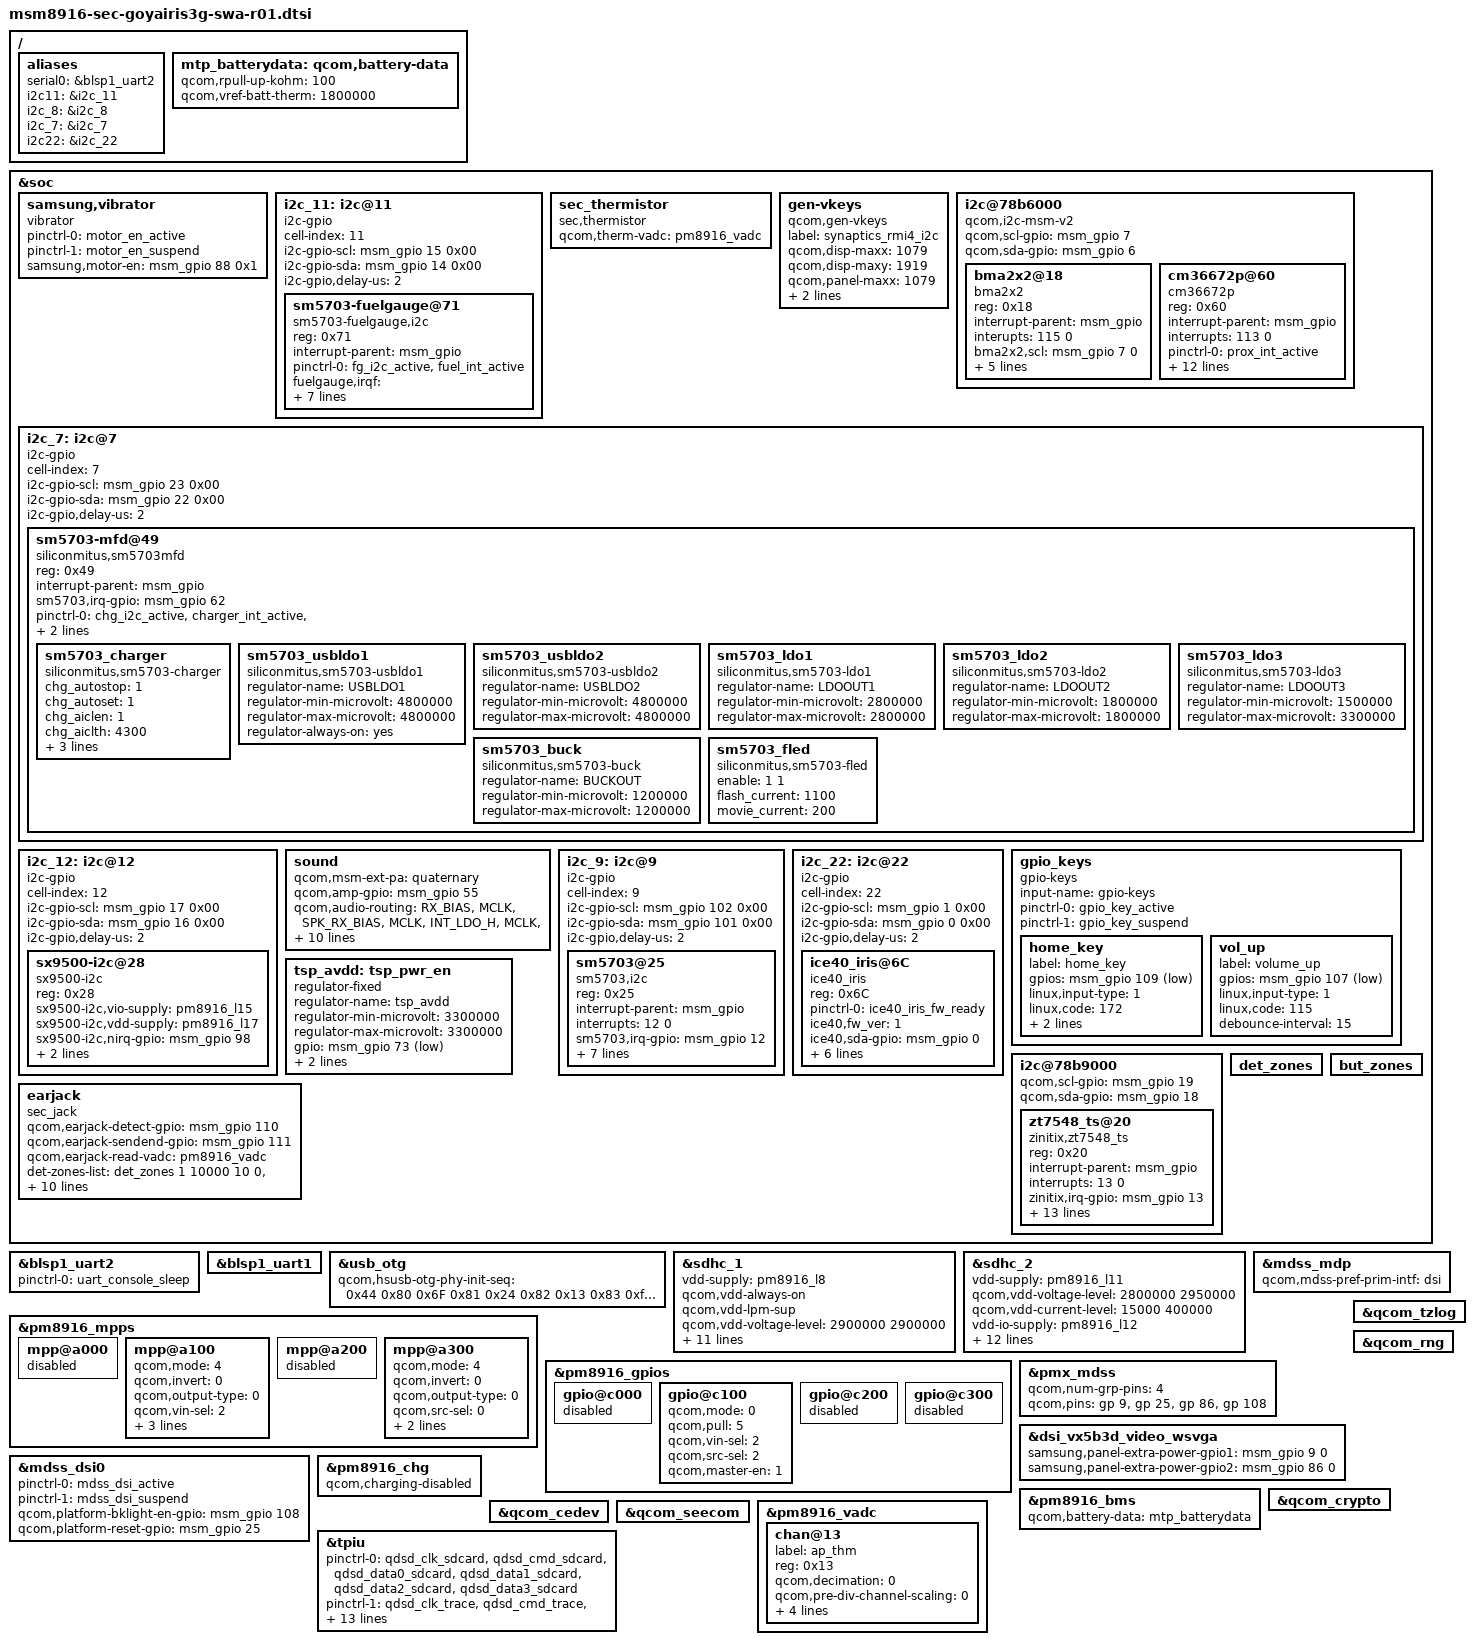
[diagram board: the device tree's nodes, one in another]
/* Copyright (c) 2014, The Linux Foundation. All rights reserved.
 *
 * This program is free software; you can redistribute it and/or modify
 * it under the terms of the GNU General Public License version 2 and
 * only version 2 as published by the Free Software Foundation.
 *
 * This program is distributed in the hope that it will be useful,
 * but WITHOUT ANY WARRANTY; without even the implied warranty of
 * MERCHANTABILITY or FITNESS FOR A PARTICULAR PURPOSE.  See the
 * GNU General Public License for more details.
 */

#include "msm8916.dtsi"
#include "msm8916-pinctrl-sec-goyairis3g-swa-r01.dtsi"
#include "msm8916-camera-sensor-goyairis3g-swa-r01.dtsi"
#include "msm8916-sec-goyairis-eur-battery-r01.dtsi"
#include "../../../../../../drivers/video/msm/mdss/samsung/VX5B3D_BA070WS1/dsi_panel_VX5B3D_BA070WS1.dtsi"

/ {
	aliases {
		serial0 = &blsp1_uart2;
		i2c11 = &i2c_11;
		i2c_8 = &i2c_8;
		i2c_7 = &i2c_7;
		i2c22 = &i2c_22;
	};
};

&soc {
	samsung,vibrator {
		compatible = "vibrator";
		pinctrl-names = "tlmm_motor_en_active","tlmm_motor_en_suspend";
		pinctrl-0 = <&motor_en_active>;
		pinctrl-1 = <&motor_en_suspend>;
		samsung,motor-en = <&msm_gpio 88 0x1>;
		status = "ok";
	};

       i2c_11:i2c@11 {
		cell-index = <11>;
		compatible = "i2c-gpio";
		i2c-gpio-scl = <&msm_gpio 15 0x00>;
		i2c-gpio-sda = <&msm_gpio 14 0x00>;
		i2c-gpio,delay-us = <2>;
		#address-cells = <1>;
		#size-cells = <0>;

		sm5703-fuelgauge@71{
			compatible = "sm5703-fuelgauge,i2c";
			reg = <0x71>;
			interrupt-parent = <&msm_gpio>;
			pinctrl-names = "default";
			pinctrl-0 = <&fg_i2c_active &fuel_int_active>;
			fuelgauge,irqf = "IRQF_TRIGGER_FALLING + IRQF_ONESHOT + IRQF_NO_SUSPEND";
			fuelgauge,fuel_int = <&msm_gpio 121 0x1>;
			fuelgauge,capacity_max = <1000>;
			fuelgauge,capacity_max_margin = <50>;
			fuelgauge,capacity_min = <0>;
			fuelgauge,capacity_calculation_type = <0x1F>;
			fuelgauge,fuel_alert_soc = <1>;
		};
	};

	sec_thermistor {
		compatible = "sec,thermistor";
		qcom,therm-vadc = <&pm8916_vadc>;
	};

	gen-vkeys {
		compatible = "qcom,gen-vkeys";
		label = "synaptics_rmi4_i2c";
		qcom,disp-maxx = <1079>;
		qcom,disp-maxy = <1919>;
		qcom,panel-maxx = <1079>;
		qcom,panel-maxy = <2084>;
		qcom,key-codes = <158 139 172 217>;
	};
/* GPIO_0 is used by LCD
	i2c@78ba000 {
		nfc-nci@e {
			compatible = "qcom,nfc-nci";
			reg = <0x0e>;
			qcom,irq-gpio = <&msm_gpio 21 0x00>;
			qcom,dis-gpio = <&msm_gpio 20 0x00>;
			qcom,clk-src = "BBCLK2";
			qcom,clk-en-gpio = <&msm_gpio 0 0x00>;
			interrupt-parent = <&msm_gpio>;
			interrupts = <21 0>;
			interrupt-names = "nfc_irq";
			pinctrl-names = "nfc_active","nfc_suspend";
			pinctrl-0 = <&nfc_int_active &nfc_disable_active>;
			pinctrl-1 = <&nfc_int_suspend &nfc_disable_suspend>;
			qcom,clk-gpio = <&pm8916_gpios 2 0>;
			clocks = <&clock_rpm clk_bb_clk2_pin>;
			clock-names = "ref_clk";
		};
	};
*/
	i2c@78b6000 { /* BLSP1 QUP2 */
		compatible = "qcom,i2c-msm-v2";
		qcom,scl-gpio = <&msm_gpio 7 0>;
		qcom,sda-gpio = <&msm_gpio 6 0>;

		bma2x2@18{
			compatible = "bma2x2";
			reg = <0x18>;
                        interrupt-parent = <&msm_gpio>;
			interupts= <115 0>;
			bma2x2,scl = <&msm_gpio 7 0>;
			bma2x2,sda = <&msm_gpio 6 0>;
			bma2x2,gpio_int1 = <&msm_gpio 115 0x00>;
			bma2x2,accel_place = <4>;
			bma2x2,vdd-supply = <&pm8916_l17>;
			bma2x2,vio-supply = <&pm8916_l5>;
		};

		cm36672p@60 {
			compatible = "cm36672p";
			reg = <0x60>;
			interrupt-parent = <&msm_gpio>;
			interrupts = <113 0>;
			pinctrl-names = "default";
			pinctrl-0 = <&prox_int_active>;
			pinctrl-1 = <&prox_int_suspend>;
			cm36672p,leden_gpio = <&msm_gpio 8 0x1>;
			cm36672p,irq_gpio = <&msm_gpio 113 0x1>;
			cm36672p,vdd-supply = <&pm8916_l17>;
			cm36672p,vio-supply = <&pm8916_l5>;
			cm36672p,default_hi_thd = <125>;
			cm36672p,default_low_thd = <95>;
			cm36672p,cancel_hi_thd = <105>;
			cm36672p,cancel_low_thd = <75>;
			cm36672p,ps_it = <4>;
			cm36672p,led_current = <5>;
			cm36672p,default_trim = <20>;
			};
	};

	i2c_7:i2c@7 {
		cell-index = <7>;
		compatible = "i2c-gpio";
		i2c-gpio-scl = <&msm_gpio 23 0x00>;
		i2c-gpio-sda = <&msm_gpio 22 0x00>;
		i2c-gpio,delay-us = <2>;
		#address-cells = <1>;
		#size-cells = <0>;

		sm5703-mfd@49{
			compatible = "siliconmitus,sm5703mfd";
			reg = <0x49>;
			interrupt-parent = <&msm_gpio>;
			sm5703,irq-gpio = <&msm_gpio 62 0x00>;
			pinctrl-names = "default";
			pinctrl-0 = <&chg_i2c_active &charger_int_active &if_pmic_rst_active &chg_en_active>;
			sm5703,mrstb-gpio = <&msm_gpio 24 0x00>;

			sm5703_charger {
				compatible = "siliconmitus,sm5703-charger";
				chg_autostop = <1>;
				chg_autoset = <1>;
				chg_aiclen = <1>;
				chg_aiclth = <4300>;
				fg_vol_val = <4350>;
				fg_soc_val = <95>;
				fg_curr_avr_val = <150>;
			};

			sm5703_usbldo1 {
				compatible = "siliconmitus,sm5703-usbldo1";
				regulator-name = "USBLDO1"; /* change name by yourself */
				regulator-min-microvolt = <4800000>;
				regulator-max-microvolt = <4800000>; /* max == min then apply_uV = 1 */
				/* regulator-microvolt-offset = < >; optional*/
				/* regulator-boot-on = "yes"; optional, exist = enabled */
				regulator-always-on = "yes";
				/* regulator-ramp-delay = <100>; optional*/
			};

			sm5703_usbldo2 {
				compatible = "siliconmitus,sm5703-usbldo2";
				regulator-name = "USBLDO2"; /* change name by yourself */
				regulator-min-microvolt = <4800000>;
				regulator-max-microvolt = <4800000>; /* max == min then apply_uV = 1 */
				/* regulator-microvolt-offset = < >; optional*/
				/* regulator-boot-on = "yes"; optional, exist = enabled */
				/* regulator-always-on = "yes"; optional, exist = enabled */
				/* regulator-ramp-delay = <100>; optional*/
			};

			sm5703_ldo1 {
				compatible = "siliconmitus,sm5703-ldo1";
				regulator-name = "LDOOUT1"; /* change name by yourself */
				regulator-min-microvolt = <2800000>;
				regulator-max-microvolt = <2800000>; /* max == min then apply_uV = 1 */
				/* regulator-microvolt-offset = < >; optional*/
				/* regulator-boot-on = "yes"; optional, exist = enabled */
				/* regulator-always-on = "yes"; optional, exist = enabled */
				/* regulator-ramp-delay = <100>; optional*/
			};

			sm5703_ldo2 {
				compatible = "siliconmitus,sm5703-ldo2";
				regulator-name = "LDOOUT2"; /* change name by yourself */
				regulator-min-microvolt = <1800000>;
				regulator-max-microvolt = <1800000>; /* max == min then apply_uV = 1 */
				/* regulator-microvolt-offset = < >; optional*/
				/* regulator-boot-on = "yes"; optional, exist = enabled */
				/* regulator-always-on = "yes"; optional, exist = enabled */
				/* regulator-ramp-delay = <100>; optional*/
			};

			sm5703_ldo3 {
				compatible = "siliconmitus,sm5703-ldo3";
				regulator-name = "LDOOUT3"; /* change name by yourself */
				regulator-min-microvolt = <1500000>;
				regulator-max-microvolt = <3300000>; /* max == min then apply_uV = 1 */
				/* regulator-microvolt-offset = < >; optional*/
				/* regulator-boot-on = "yes"; optional, exist = enabled */
				/* regulator-always-on = "yes"; optional, exist = enabled */
				/* regulator-ramp-delay = <100>; optional*/
			};

			sm5703_buck {
				compatible = "siliconmitus,sm5703-buck";
				regulator-name = "BUCKOUT"; /* change name by yourself */
				regulator-min-microvolt = <1200000>;
				regulator-max-microvolt = <1200000>; /* max == min then apply_uV = 1 */
				/* regulator-microvolt-offset = < >; optional*/
				/* regulator-boot-on = "yes"; optional, exist = enabled */
				/* regulator-always-on = "yes"; optional, exist = enabled */
				/* regulator-ramp-delay = <100>; optional*/

			};

			sm5703_fled {
				compatible = "siliconmitus,sm5703-fled";
				enable = <1 1>;
				flash_current = <1100>;
				movie_current = <200>;
				/*sm5703,led1-gpio = <&msm_gpio 34 0x00>;
				sm5703,led2-gpio = <&msm_gpio 36 0x00>; 
				pinctrl-names = "fled_default","fled_sleep";
				pinctrl-0 = <&cam_flash_active>;
				pinctrl-1 = <&cam_flash_sleep>;*/
			};
		};
	};

	i2c_12:i2c@12 {
		cell-index = <12>;
		compatible = "i2c-gpio";
		i2c-gpio-scl = <&msm_gpio 17 0x00>;
		i2c-gpio-sda = <&msm_gpio 16 0x00>;
		i2c-gpio,delay-us = <2>;
		#address-cells = <1>;
		#size-cells = <0>;
		sx9500-i2c@28 {
			compatible = "sx9500-i2c";
			reg = <0x28>;
			sx9500-i2c,vio-supply = <&pm8916_l15>;
			sx9500-i2c,vdd-supply = <&pm8916_l17>;
			sx9500-i2c,nirq-gpio = <&msm_gpio 98 0x00>;
			sx9500-i2c,i2c-pull-up = <1>;
			pinctrl-names = "default";
			pinctrl-0 = <&grip_i2c_active &grip_int_active>;
		};
	};

	/* Over-riding model specific changes */
	sound {
		qcom,msm-ext-pa = "quaternary";
		qcom,amp-gpio = <&msm_gpio 55 0x0>;
		qcom,audio-routing =
			"RX_BIAS", "MCLK",
			"SPK_RX_BIAS", "MCLK",
			"INT_LDO_H", "MCLK",
			"MIC BIAS External", "Handset Mic",
			"MIC BIAS External", "Secondary Mic",
			"AMIC1", "MIC BIAS External",
			"AMIC2", "Headset Mic",
			"AMIC3", "MIC BIAS External";
		pinctrl-names = "cdc_lines_act",
				"cdc_lines_sus",
				"cdc_lines_quat_ext_act",
				"cdc_lines_quat_ext_sus";
		pinctrl-0 = <&cdc_pdm_lines_act>;
		pinctrl-1 = <&cdc_pdm_lines_sus>;
		pinctrl-2 = <&cdc_pdm_lines_act &ext_cdc_tlmm_lines_act>;
		pinctrl-3 = <&cdc_pdm_lines_sus &ext_cdc_tlmm_lines_sus>;
	};

	i2c_9:i2c@9 { /*SM5703 GPIO-I2C*/
		cell-index = <9>;
		compatible = "i2c-gpio";
		i2c-gpio-scl = <&msm_gpio 102 0x00>;
		i2c-gpio-sda = <&msm_gpio 101 0x00>;
		i2c-gpio,delay-us = <2>;
		#address-cells = <1>;
		#size-cells = <0>;

		sm5703@25{
			compatible = "sm5703,i2c";
			reg = <0x25>;
			interrupt-parent = <&msm_gpio>;
			interrupts= <12 0>;
			sm5703,irq-gpio = <&msm_gpio 12 0x00>;
			sm5703,gpio-sda = <&msm_gpio 101 0x00>;
			sm5703,gpio-scl = <&msm_gpio 102 0x00>;
			sm5703,uarton-gpio = <&msm_gpio 114 0x00>;
			pinctrl-names = "sm5703_i2c_active","sm5703_i2c_suspend";
			pinctrl-0 = <&muic_i2c_active &muic_int_pin &muic_chg_det>;
			pinctrl-1 = <&muic_i2c_suspend &muic_int_pin &muic_chg_det>;
		};
	};

	i2c_22:i2c@22 {
		cell-index = <22>;
		compatible = "i2c-gpio";
		i2c-gpio-scl = <&msm_gpio 1 0x00>;
		i2c-gpio-sda = <&msm_gpio 0 0x00>;
		i2c-gpio,delay-us = <2>;
		#address-cells = <1>;
		#size-cells = <0>;

		ice40_iris@6C {
			compatible = "ice40_iris";
			reg = <0x6C>;
			pinctrl-names = "ice40_iris_fw_ready";
			pinctrl-0 = <&ice40_iris_fw_ready>;
			ice40,fw_ver = <1>;
			ice40,sda-gpio = <&msm_gpio 0 0x00>;
			ice40,scl-gpio = <&msm_gpio 1 0x00>;
			ice40,cresetb = <&msm_gpio 20 0x00>;
			ice40,cdone = <&msm_gpio 21 0x00>;
			ice40,reset_n = <&msm_gpio 49 0x00>;
			ice40,led_tz = <&msm_gpio 34 0x00>;
			clocks = <&clock_rpm clk_bb_clk2>;
			clock-names = "fpga_clock";
		};
	};

};

&blsp1_uart2 {
	status = "ok";
	pinctrl-names = "default";
	pinctrl-0 = <&uart_console_sleep>;
};

&soc {
	gpio_keys {
		compatible = "gpio-keys";
		input-name = "gpio-keys";
		pinctrl-names = "tlmm_gpio_key_active","tlmm_gpio_key_suspend";
		pinctrl-0 = <&gpio_key_active>;
		pinctrl-1 = <&gpio_key_suspend>;

		home_key {
			label = "home_key";
			gpios = <&msm_gpio 109 0x1>;
			linux,input-type = <1>;
			linux,code = <172>;
			gpio-key,wakeup;
			debounce-interval = <15>;
		};

		vol_up {
			label = "volume_up";
			gpios = <&msm_gpio 107 0x1>;
			linux,input-type = <1>;
			linux,code = <115>;
			debounce-interval = <15>;
		};
	};

	tsp_avdd:tsp_pwr_en {
		compatible = "regulator-fixed";
		regulator-name = "tsp_avdd";
		regulator-min-microvolt = <3300000>;
		regulator-max-microvolt = <3300000>;
		gpio = <&msm_gpio 73 0x1>;
		enable-active-high;
		regulator-boot-on;
	};

	i2c@78b9000 { /* BLSP1 QUP5 */
		qcom,scl-gpio = <&msm_gpio 19 0>;
		qcom,sda-gpio = <&msm_gpio 18 0>;
                status = "okay";
		zt7548_ts@20 {
			compatible = "zinitix,zt7548_ts";
			reg = <0x20>;
			interrupt-parent = <&msm_gpio>;
			interrupts = <13 0>; /* TSP int gpio */
			zinitix,irq-gpio = <&msm_gpio 13 0x00>; /*TSP IRQ GPIO */
			zinitix,scl-gpio = <&msm_gpio 19 0x00>;
			zinitix,sda-gpio = <&msm_gpio 18 0x00>;
			pinctrl-names = "tsp_i2c_gpio_active", "tsp_i2c_suspend";
			pinctrl-0 = <&tsp_irq_gpio &tsp_en_resume>;
			pinctrl-1 = <&tsp_en_suspend>;
			avdd-supply = <&tsp_avdd>;
			vddo-supply = <&pm8916_l6>;
			zt7548,x_resolution = <2400>;
			zt7548,y_resolution = <4096>;
			zt7548,model_name = "T116";
			zt7548,fw_name = "tsp_zinitix/zt7548_goyairis.fw";
			zt7548,reg_boot_on;
			zt7548,use_dummy_key;
			zt7548,calculate_dnd_from_fw;
		};
	};

	det_zones: det_zones {
		#list-det-cells = <4>;
	};

	but_zones: but_zones {
		#list-but-cells = <3>;
	};

	earjack {
		compatible = "sec_jack";
		qcom,earjack-detect-gpio = <&msm_gpio 110 0x0>;
		qcom,earjack-sendend-gpio = <&msm_gpio 111 0x0>;
		qcom,earjack-read-vadc = <&pm8916_vadc>;

		det-zones-list = <&det_zones 1 10000 10 0>,
				 <&det_zones 965 10000 10 0>,
				 <&det_zones 1000 10000 10 1>,
				 <&det_zones 1900 10000 10 1>;
		but-zones-list = <&but_zones 0 1 304>,
				 <&but_zones 3 305 350>,
				 <&but_zones 1 351 466>,
				 <&but_zones 2 467 760>;
		btn-adc-read-count = <8>;
		mpp-channel-scaling = <2 1 1>;
		pinctrl-names = "earjack_gpio_active","earjack_gpio_suspend";
		pinctrl-0 = <&earjack_det_act &earjack_switch_act>;
		pinctrl-1 = <&earjack_det_sus &earjack_switch_sus>;
	};
};

&blsp1_uart1 {
	status = "ok";
};

&usb_otg {
	qcom,hsusb-otg-phy-init-seq =
					<0x44 0x80 0x6F 0x81 0x24 0x82 0x13 0x83 0xffffffff>;
};

&sdhc_1 {
	vdd-supply = <&pm8916_l8>;
	qcom,vdd-always-on;
	qcom,vdd-lpm-sup;
	qcom,vdd-voltage-level = <2900000 2900000>;
	qcom,vdd-current-level = <200 400000>;

	vdd-io-supply = <&pm8916_l5>;
	qcom,vdd-io-always-on;
	qcom,vdd-io-lpm-sup;
	qcom,vdd-io-voltage-level = <1800000 1800000>;
	qcom,vdd-io-current-level = <200 60000>;

	pinctrl-names = "active", "sleep";
	pinctrl-0 = <&sdc1_clk_on &sdc1_cmd_on &sdc1_data_on>;
	pinctrl-1 = <&sdc1_clk_off &sdc1_cmd_off &sdc1_data_off>;

	qcom,nonremovable;

	status = "ok";
};

&sdhc_2 {
	vdd-supply = <&pm8916_l11>;
	qcom,vdd-voltage-level = <2800000 2950000>;
	qcom,vdd-current-level = <15000 400000>;

	vdd-io-supply = <&pm8916_l12>;
	qcom,vdd-io-voltage-level = <1800000 2950000>;
	qcom,vdd-io-current-level = <200 50000>;

	pinctrl-names = "active", "sleep";
	pinctrl-0 = <&sdc2_clk_on &sdc2_cmd_on &sdc2_data_on &sdc2_cd_on>;
	pinctrl-1 = <&sdc2_clk_off &sdc2_cmd_off &sdc2_data_off &sdc2_cd_off>;

	#address-cells = <0>;
	interrupt-parent = <&sdhc_2>;
	interrupts = <0 1 2>;
	#interrupt-cells = <1>;
	interrupt-map-mask = <0xffffffff>;
	interrupt-map = <0 &intc 0 125 0
			1 &intc 0 221 0
			2 &msm_gpio 38 0>;
	interrupt-names = "hc_irq", "pwr_irq", "status_irq";
	cd-gpios = <&msm_gpio 38 0x1>;

	status = "ok";
};

&pm8916_mpps {
	mpp@a000 { /* MPP 1 */
		/* VDD_PX */
		status = "disabled";
	};

	mpp@a100 { /* MPP 2 */
		status = "ok";
		qcom,mode = <4>; // AIN input
		qcom,invert = <0>; //No Invert
		qcom,output-type = <0>; //CMOS
		qcom,vin-sel = <2>; //PM8971_S3 1.8v
		qcom,src-sel = <0>; //MPP Constant
		qcom,ain-route = <1>; // QPNP_PIN_AIN_AMUX_CH6 = 1 for MPP2
		qcom,master-en = <1>; // Function constant
	};

	mpp@a200 { /* MPP 3 */
		/* VREF DAC */
		status = "disabled";
	};

	mpp@a300 { /* MPP 4 */
		status = "ok";
		qcom,mode = <4>;		/* AIN Input */
		qcom,invert = <0>;		/* Disable invert */
		qcom,output-type = <0>;		/* CMOS */
		qcom,src-sel = <0>;		/* /MPP Constant */
		qcom,ain-route = <3>;		/* QPNP_PIN_AIN_AMUX_CH8 = 3 for MPP4 */
		qcom,master-en = <1>;		/* Enable MPP */
	};
};

&pm8916_gpios {
	gpio@c000 { /* GPIO 1 */
		/* Battery UICC Alarm */
		status = "disabled";
	};

	gpio@c100 { /* GPIO 2 */
		/* NFC_CLK_REQ */
		qcom,mode = <0>; /* QPNP_PIN_MODE_DIG_IN */
		qcom,pull = <5>; /* QPNP_PIN_PULL_NO */
		qcom,vin-sel = <2>; /* QPNP_PIN_VIN2 */
		qcom,src-sel = <2>; /* QPNP_PIN_SEL_FUNC_1 */
		qcom,master-en = <1>;
	};

	gpio@c200 { /* GPIO 3 */
		/* External regulator control for WTR */
		status = "disabled";
	};

	gpio@c300 { /* GPIO 4 */
		/* External regulator control for APC */
		status = "disabled";
	};
};

&mdss_mdp {
	qcom,mdss-pref-prim-intf = "dsi";
};

&pmx_mdss {
	qcom,num-grp-pins = <4>;
 	qcom,pins = <&gp 9>,<&gp 25>,<&gp 86>,<&gp 108>;
 };

&dsi_vx5b3d_video_wsvga{
	samsung,panel-extra-power-gpio1 = <&msm_gpio 9 0>;/*lvds on 3.3V*/
	samsung,panel-extra-power-gpio2 = <&msm_gpio 86 0>;/*lcd 3.3V*/

};

&mdss_dsi0 {
	pinctrl-names = "mdss_default", "mdss_sleep";
	pinctrl-0 = <&mdss_dsi_active>;
	pinctrl-1 = <&mdss_dsi_suspend >;
	qcom,platform-bklight-en-gpio = <&msm_gpio 108 0>; /*lcd blic on*/
	qcom,platform-reset-gpio = <&msm_gpio 25 0>;

};

&pm8916_chg {
	status = "ok";
	qcom,charging-disabled;
};

/ {
	mtp_batterydata: qcom,battery-data {
		qcom,rpull-up-kohm = <100>;
		qcom,vref-batt-therm = <1800000>;

		#include "batterydata-palladium.dtsi"
	};
};

&pm8916_bms {
	status = "ok";
	qcom,battery-data = <&mtp_batterydata>;
};

&qcom_tzlog {
	status = "okay";
};

&qcom_rng {
	status = "okay";
};

&qcom_crypto {
	status = "okay";
};

&qcom_cedev {
	status = "okay";
};

&qcom_seecom {
	status = "okay";
};

/* CoreSight */
&tpiu {
      pinctrl-names = "sdcard", "trace", "swduart",
		      "swdtrc", "jtag", "spmi";
       /* NIDnT */
      pinctrl-0 = <&qdsd_clk_sdcard &qdsd_cmd_sdcard
                  &qdsd_data0_sdcard &qdsd_data1_sdcard
                  &qdsd_data2_sdcard &qdsd_data3_sdcard>;
      pinctrl-1 = <&qdsd_clk_trace &qdsd_cmd_trace
                  &qdsd_data0_trace &qdsd_data1_trace
                  &qdsd_data2_trace &qdsd_data3_trace>;
      pinctrl-2 = <&qdsd_cmd_swduart &qdsd_data0_swduart
                  &qdsd_data1_swduart &qdsd_data2_swduart
                  &qdsd_data3_swduart>;
      pinctrl-3 = <&qdsd_clk_swdtrc &qdsd_cmd_swdtrc
                  &qdsd_data0_swdtrc &qdsd_data1_swdtrc
                  &qdsd_data2_swdtrc &qdsd_data3_swdtrc>;
      pinctrl-4 = <&qdsd_cmd_jtag &qdsd_data0_jtag
                  &qdsd_data1_jtag &qdsd_data2_jtag
                  &qdsd_data3_jtag>;
      pinctrl-5 = <&qdsd_clk_spmi &qdsd_cmd_spmi
                  &qdsd_data0_spmi &qdsd_data3_spmi>;
};

&pm8916_vadc {
	chan@13 {
		label = "ap_thm";
		reg = <0x13>;	/* channel 19 for MPP4 , 1:1scale */
		qcom,decimation = <0>;
		qcom,pre-div-channel-scaling = <0>;	/* 1:1scale */
		qcom,calibration-type = "ratiometric";
		qcom,scale-function = <1>;
		qcom,hw-settle-time = <2>;
		qcom,fast-avg-setup = <0>;
	};
};
